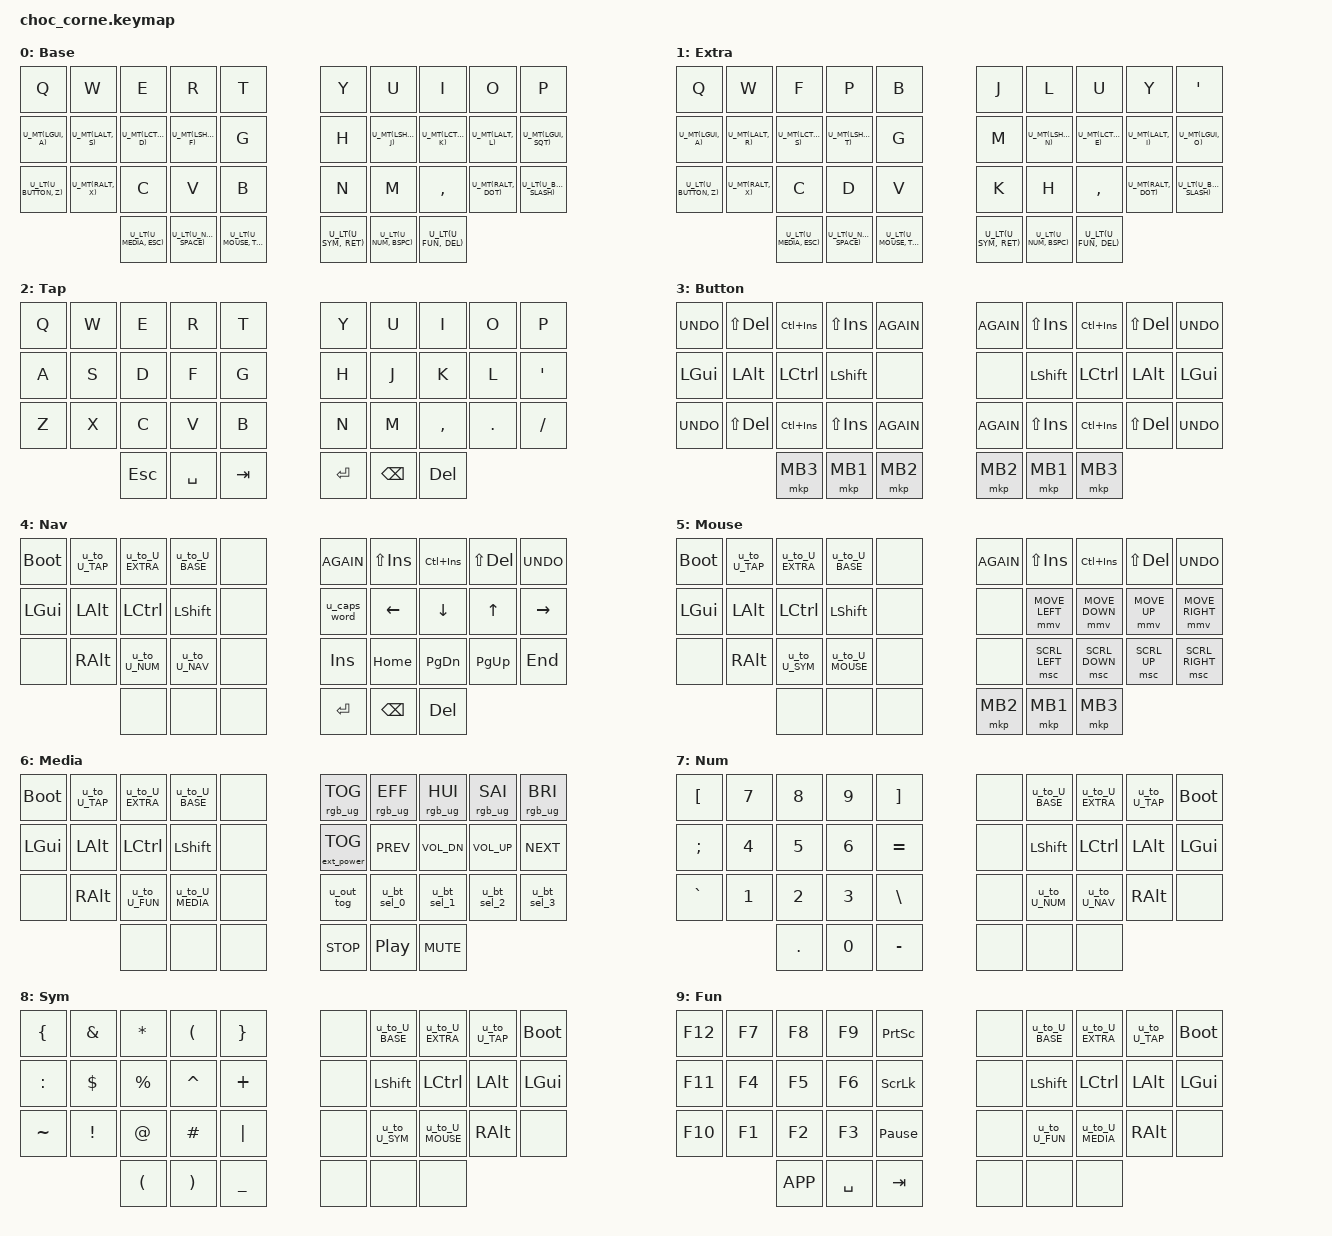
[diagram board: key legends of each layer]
/*
 * Copyright (c) 2020 The ZMK Contributors
 *
 * SPDX-License-Identifier: MIT
 */

#include <behaviors.dtsi>
#include <behaviors/mouse_keys.dtsi>
#include <dt-bindings/zmk/keys.h>
#include <dt-bindings/zmk/bt.h>
#include <dt-bindings/zmk/rgb.h>
#include <dt-bindings/zmk/outputs.h>
#include <dt-bindings/zmk/ext_power.h>
#include <dt-bindings/zmk/pointing.h>

// Layer indices
#define U_BASE   0
#define U_EXTRA  1
#define U_TAP    2
#define U_BUTTON 3
#define U_NAV    4
#define U_MOUSE  5
#define U_MEDIA  6
#define U_NUM    7
#define U_SYM    8
#define U_FUN    9

// Tapping term
#define U_TAPPING_TERM 200

// Placeholder keys
#define U_NP &none  // key not present
#define U_NA &none  // not available
#define U_NU &none  // not used

// Clipboard (default / X11)
#define U_RDO &kp K_AGAIN
#define U_PST &kp LS(INS)
#define U_CPY &kp LC(INS)
#define U_CUT &kp LS(DEL)
#define U_UND &kp K_UNDO

// Mouse
#define ZMK_POINTING_DEFAULT_MOVE_VAL 1250
#define ZMK_POINTING_DEFAULT_SCRL_VAL 100
#define U_BTN1 &mkp MB1
#define U_BTN2 &mkp MB2
#define U_BTN3 &mkp MB3
#define U_MS_D &mmv MOVE_DOWN
#define U_MS_L &mmv MOVE_LEFT
#define U_MS_R &mmv MOVE_RIGHT
#define U_MS_U &mmv MOVE_UP
#define U_WH_D &msc SCRL_DOWN
#define U_WH_L &msc SCRL_LEFT
#define U_WH_R &msc SCRL_RIGHT
#define U_WH_U &msc SCRL_UP

// RGB / ext_power
#define U_RGB_TOG &rgb_ug RGB_TOG
#define U_RGB_EFF &rgb_ug RGB_EFF
#define U_RGB_HUI &rgb_ug RGB_HUI
#define U_RGB_SAI &rgb_ug RGB_SAI
#define U_RGB_BRI &rgb_ug RGB_BRI
#define U_EP_TOG  &ext_power EP_TOG

// Boot
#define U_BOOT &bootloader

/ {
    behaviors {
        // Hold-tap: mod-tap
        u_mt: u_mt {
            compatible = "zmk,behavior-hold-tap";
            #binding-cells = <2>;
            tapping-term-ms = <U_TAPPING_TERM>;
            flavor = "tap-preferred";
            bindings = <&kp>, <&kp>;
        };
        // Hold-tap: layer-tap
        u_lt: u_lt {
            compatible = "zmk,behavior-hold-tap";
            #binding-cells = <2>;
            tapping-term-ms = <U_TAPPING_TERM>;
            flavor = "tap-preferred";
            bindings = <&mo>, <&kp>;
        };
        // Caps word / caps lock morph
        u_caps_word: u_caps_word {
            compatible = "zmk,behavior-mod-morph";
            #binding-cells = <0>;
            bindings = <&caps_word>, <&kp CAPS>;
            mods = <(MOD_LSFT|MOD_RSFT)>;
        };
        // Output toggle morph (toggle / force USB)
        u_out_tog: u_out_tog {
            compatible = "zmk,behavior-mod-morph";
            #binding-cells = <0>;
            bindings = <&out OUT_TOG>, <&out OUT_USB>;
            mods = <(MOD_LSFT|MOD_RSFT)>;
        };
        // Bluetooth select + clear on shift
        u_bt_sel_0: u_bt_sel_0 {
            compatible = "zmk,behavior-mod-morph";
            #binding-cells = <0>;
            bindings = <&bt BT_SEL 0>, <&bt_sel_clr_0>;
            mods = <(MOD_LSFT|MOD_RSFT)>;
        };
        u_bt_sel_1: u_bt_sel_1 {
            compatible = "zmk,behavior-mod-morph";
            #binding-cells = <0>;
            bindings = <&bt BT_SEL 1>, <&bt_sel_clr_1>;
            mods = <(MOD_LSFT|MOD_RSFT)>;
        };
        u_bt_sel_2: u_bt_sel_2 {
            compatible = "zmk,behavior-mod-morph";
            #binding-cells = <0>;
            bindings = <&bt BT_SEL 2>, <&bt_sel_clr_2>;
            mods = <(MOD_LSFT|MOD_RSFT)>;
        };
        u_bt_sel_3: u_bt_sel_3 {
            compatible = "zmk,behavior-mod-morph";
            #binding-cells = <0>;
            bindings = <&bt BT_SEL 3>, <&bt_sel_clr_3>;
            mods = <(MOD_LSFT|MOD_RSFT)>;
        };
        u_bt_sel_4: u_bt_sel_4 {
            compatible = "zmk,behavior-mod-morph";
            #binding-cells = <0>;
            bindings = <&bt BT_SEL 4>, <&bt_sel_clr_4>;
            mods = <(MOD_LSFT|MOD_RSFT)>;
        };
        // Layer-switch tap-dances (double-tap to activate)
        u_to_U_BASE: u_to_U_BASE {
            compatible = "zmk,behavior-tap-dance";
            #binding-cells = <0>;
            tapping-term-ms = <U_TAPPING_TERM>;
            bindings = <&none>, <&to U_BASE>;
        };
        u_to_U_EXTRA: u_to_U_EXTRA {
            compatible = "zmk,behavior-tap-dance";
            #binding-cells = <0>;
            tapping-term-ms = <U_TAPPING_TERM>;
            bindings = <&none>, <&to U_EXTRA>;
        };
        u_to_U_TAP: u_to_U_TAP {
            compatible = "zmk,behavior-tap-dance";
            #binding-cells = <0>;
            tapping-term-ms = <U_TAPPING_TERM>;
            bindings = <&none>, <&to U_TAP>;
        };
        u_to_U_BUTTON: u_to_U_BUTTON {
            compatible = "zmk,behavior-tap-dance";
            #binding-cells = <0>;
            tapping-term-ms = <U_TAPPING_TERM>;
            bindings = <&none>, <&to U_BUTTON>;
        };
        u_to_U_NAV: u_to_U_NAV {
            compatible = "zmk,behavior-tap-dance";
            #binding-cells = <0>;
            tapping-term-ms = <U_TAPPING_TERM>;
            bindings = <&none>, <&to U_NAV>;
        };
        u_to_U_MOUSE: u_to_U_MOUSE {
            compatible = "zmk,behavior-tap-dance";
            #binding-cells = <0>;
            tapping-term-ms = <U_TAPPING_TERM>;
            bindings = <&none>, <&to U_MOUSE>;
        };
        u_to_U_MEDIA: u_to_U_MEDIA {
            compatible = "zmk,behavior-tap-dance";
            #binding-cells = <0>;
            tapping-term-ms = <U_TAPPING_TERM>;
            bindings = <&none>, <&to U_MEDIA>;
        };
        u_to_U_NUM: u_to_U_NUM {
            compatible = "zmk,behavior-tap-dance";
            #binding-cells = <0>;
            tapping-term-ms = <U_TAPPING_TERM>;
            bindings = <&none>, <&to U_NUM>;
        };
        u_to_U_SYM: u_to_U_SYM {
            compatible = "zmk,behavior-tap-dance";
            #binding-cells = <0>;
            tapping-term-ms = <U_TAPPING_TERM>;
            bindings = <&none>, <&to U_SYM>;
        };
        u_to_U_FUN: u_to_U_FUN {
            compatible = "zmk,behavior-tap-dance";
            #binding-cells = <0>;
            tapping-term-ms = <U_TAPPING_TERM>;
            bindings = <&none>, <&to U_FUN>;
        };
    };

    macros {
        bt_sel_clr_0: bt_sel_clr_0 {
            compatible = "zmk,behavior-macro";
            #binding-cells = <0>;
            bindings = <&bt BT_SEL 0>, <&bt BT_CLR>;
        };
        bt_sel_clr_1: bt_sel_clr_1 {
            compatible = "zmk,behavior-macro";
            #binding-cells = <0>;
            bindings = <&bt BT_SEL 1>, <&bt BT_CLR>;
        };
        bt_sel_clr_2: bt_sel_clr_2 {
            compatible = "zmk,behavior-macro";
            #binding-cells = <0>;
            bindings = <&bt BT_SEL 2>, <&bt BT_CLR>;
        };
        bt_sel_clr_3: bt_sel_clr_3 {
            compatible = "zmk,behavior-macro";
            #binding-cells = <0>;
            bindings = <&bt BT_SEL 3>, <&bt BT_CLR>;
        };
        bt_sel_clr_4: bt_sel_clr_4 {
            compatible = "zmk,behavior-macro";
            #binding-cells = <0>;
            bindings = <&bt BT_SEL 4>, <&bt BT_CLR>;
        };
    };

    &mmv {
        acceleration-exponent = <1>;
        time-to-max-speed-ms = <1500>;
        delay-ms = <0>;
    };

    keymap {
        compatible = "zmk,keymap";

// Minidox (36-key) mapping applied to miryoku layers.
// Physical layout per layer (30 alpha keys + 6 thumb keys):
//
// Row 0:  K00  K01  K02  K03  K04    K05  K06  K07  K08  K09
// Row 1:  K10  K11  K12  K13  K14    K15  K16  K17  K18  K19
// Row 2:  K20  K21  K22  K23  K24    K25  K26  K27  K28  K29
// Thumb:            K32  K33  K34    K35  K36  K37

        // ── BASE (QWERTY + home-row mods) ───────────────────────────────
        BASE {
            display-name = "Base";
            bindings = <
// ╭─────────────────────────────────────────╮ ╭─────────────────────────────────────────╮
   &kp Q              &kp W              &kp E              &kp R              &kp T              &kp Y              &kp U              &kp I              &kp O              &kp P
   U_MT(LGUI, A)      U_MT(LALT, S)      U_MT(LCTRL, D)     U_MT(LSHFT, F)     &kp G              &kp H              U_MT(LSHFT, J)     U_MT(LCTRL, K)     U_MT(LALT, L)      U_MT(LGUI, SQT)
   U_LT(U_BUTTON, Z)  U_MT(RALT, X)      &kp C              &kp V              &kp B              &kp N              &kp M              &kp COMMA          U_MT(RALT, DOT)    U_LT(U_BUTTON, SLASH)
// ╰─────────────────────────────────────────╯ ╰─────────────────────────────────────────╯
                                         U_LT(U_MEDIA, ESC) U_LT(U_NAV, SPACE) U_LT(U_MOUSE, TAB) U_LT(U_SYM, RET)   U_LT(U_NUM, BSPC)  U_LT(U_FUN, DEL)
            >;
        };

        // ── EXTRA (ColemakDH alternative base) ──────────────────────────
        EXTRA {
            display-name = "Extra";
            bindings = <
   &kp Q              &kp W              &kp F              &kp P              &kp B              &kp J              &kp L              &kp U              &kp Y              &kp SQT
   U_MT(LGUI, A)      U_MT(LALT, R)      U_MT(LCTRL, S)     U_MT(LSHFT, T)     &kp G              &kp M              U_MT(LSHFT, N)     U_MT(LCTRL, E)     U_MT(LALT, I)      U_MT(LGUI, O)
   U_LT(U_BUTTON, Z)  U_MT(RALT, X)      &kp C              &kp D              &kp V              &kp K              &kp H              &kp COMMA          U_MT(RALT, DOT)    U_LT(U_BUTTON, SLASH)
                                         U_LT(U_MEDIA, ESC) U_LT(U_NAV, SPACE) U_LT(U_MOUSE, TAB) U_LT(U_SYM, RET)   U_LT(U_NUM, BSPC)  U_LT(U_FUN, DEL)
            >;
        };

        // ── TAP (QWERTY no mods) ────────────────────────────────────────
        TAP {
            display-name = "Tap";
            bindings = <
   &kp Q   &kp W   &kp E    &kp R    &kp T    &kp Y    &kp U    &kp I     &kp O    &kp P
   &kp A   &kp S   &kp D    &kp F    &kp G    &kp H    &kp J    &kp K     &kp L    &kp SQT
   &kp Z   &kp X   &kp C    &kp V    &kp B    &kp N    &kp M    &kp COMMA &kp DOT  &kp SLASH
                   &kp ESC  &kp SPACE &kp TAB  &kp RET  &kp BSPC &kp DEL
            >;
        };

        // ── BUTTON ──────────────────────────────────────────────────────
        BUTTON {
            display-name = "Button";
            bindings = <
   U_UND           U_CUT           U_CPY           U_PST           U_RDO           U_RDO           U_PST           U_CPY           U_CUT           U_UND
   &kp LGUI        &kp LALT        &kp LCTRL       &kp LSHFT       U_NU            U_NU            &kp LSHFT       &kp LCTRL       &kp LALT        &kp LGUI
   U_UND           U_CUT           U_CPY           U_PST           U_RDO           U_RDO           U_PST           U_CPY           U_CUT           U_UND
                                   U_BTN3          U_BTN1          U_BTN2          U_BTN2          U_BTN1          U_BTN3
            >;
        };

        // ── NAV ─────────────────────────────────────────────────────────
        NAV {
            display-name = "Nav";
            bindings = <
   U_BOOT          &u_to_U_TAP     &u_to_U_EXTRA   &u_to_U_BASE    U_NA            U_RDO           U_PST           U_CPY           U_CUT           U_UND
   &kp LGUI        &kp LALT        &kp LCTRL       &kp LSHFT       U_NA            &u_caps_word    &kp LEFT        &kp DOWN        &kp UP          &kp RIGHT
   U_NA            &kp RALT        &u_to_U_NUM     &u_to_U_NAV     U_NA            &kp INS         &kp HOME        &kp PG_DN       &kp PG_UP       &kp END
                                   U_NA            U_NA            U_NA            &kp RET         &kp BSPC        &kp DEL
            >;
        };

        // ── MOUSE ───────────────────────────────────────────────────────
        MOUSE {
            display-name = "Mouse";
            bindings = <
   U_BOOT          &u_to_U_TAP     &u_to_U_EXTRA   &u_to_U_BASE    U_NA            U_RDO           U_PST           U_CPY           U_CUT           U_UND
   &kp LGUI        &kp LALT        &kp LCTRL       &kp LSHFT       U_NA            U_NU            U_MS_L          U_MS_D          U_MS_U          U_MS_R
   U_NA            &kp RALT        &u_to_U_SYM     &u_to_U_MOUSE   U_NA            U_NU            U_WH_L          U_WH_D          U_WH_U          U_WH_R
                                   U_NA            U_NA            U_NA            U_BTN2          U_BTN1          U_BTN3
            >;
        };

        // ── MEDIA ───────────────────────────────────────────────────────
        MEDIA {
            display-name = "Media";
            bindings = <
   U_BOOT          &u_to_U_TAP     &u_to_U_EXTRA   &u_to_U_BASE    U_NA            U_RGB_TOG       U_RGB_EFF       U_RGB_HUI       U_RGB_SAI       U_RGB_BRI
   &kp LGUI        &kp LALT        &kp LCTRL       &kp LSHFT       U_NA            U_EP_TOG        &kp C_PREV      &kp C_VOL_DN    &kp C_VOL_UP    &kp C_NEXT
   U_NA            &kp RALT        &u_to_U_FUN     &u_to_U_MEDIA   U_NA            &u_out_tog      &u_bt_sel_0     &u_bt_sel_1     &u_bt_sel_2     &u_bt_sel_3
                                   U_NA            U_NA            U_NA            &kp C_STOP      &kp C_PP        &kp C_MUTE
            >;
        };

        // ── NUM ─────────────────────────────────────────────────────────
        NUM {
            display-name = "Num";
            bindings = <
   &kp LBKT        &kp N7          &kp N8          &kp N9          &kp RBKT        U_NA            &u_to_U_BASE    &u_to_U_EXTRA   &u_to_U_TAP     U_BOOT
   &kp SEMI        &kp N4          &kp N5          &kp N6          &kp EQUAL       U_NA            &kp LSHFT       &kp LCTRL       &kp LALT        &kp LGUI
   &kp GRAVE       &kp N1          &kp N2          &kp N3          &kp BSLH        U_NA            &u_to_U_NUM     &u_to_U_NAV     &kp RALT        U_NA
                                   &kp DOT         &kp N0          &kp MINUS       U_NA            U_NA            U_NA
            >;
        };

        // ── SYM ─────────────────────────────────────────────────────────
        SYM {
            display-name = "Sym";
            bindings = <
   &kp LBRC        &kp AMPS        &kp ASTRK       &kp LPAR        &kp RBRC        U_NA            &u_to_U_BASE    &u_to_U_EXTRA   &u_to_U_TAP     U_BOOT
   &kp COLON       &kp DLLR        &kp PRCNT       &kp CARET       &kp PLUS        U_NA            &kp LSHFT       &kp LCTRL       &kp LALT        &kp LGUI
   &kp TILDE       &kp EXCL        &kp AT          &kp HASH        &kp PIPE        U_NA            &u_to_U_SYM     &u_to_U_MOUSE   &kp RALT        U_NA
                                   &kp LPAR        &kp RPAR        &kp UNDER       U_NA            U_NA            U_NA
            >;
        };

        // ── FUN ─────────────────────────────────────────────────────────
        FUN {
            display-name = "Fun";
            bindings = <
   &kp F12         &kp F7          &kp F8          &kp F9          &kp PSCRN       U_NA            &u_to_U_BASE    &u_to_U_EXTRA   &u_to_U_TAP     U_BOOT
   &kp F11         &kp F4          &kp F5          &kp F6          &kp SLCK        U_NA            &kp LSHFT       &kp LCTRL       &kp LALT        &kp LGUI
   &kp F10         &kp F1          &kp F2          &kp F3          &kp PAUSE_BREAK U_NA            &u_to_U_FUN     &u_to_U_MEDIA   &kp RALT        U_NA
                                   &kp K_APP       &kp SPACE       &kp TAB         U_NA            U_NA            U_NA
            >;
        };
    };
};
